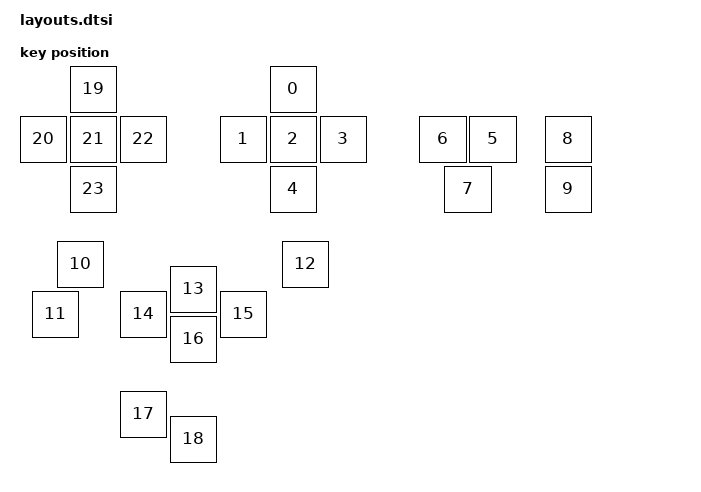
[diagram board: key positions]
#include <physical_layouts.dtsi>

/ {
    physical_layout0: physical_layout0 {
        compatible = "zmk,physical-layout";
        display-name = "Layout";
        keys
          =<&key_physical_attrs 100 100 500 0 0 0 0>
,<&key_physical_attrs 100 100 400 100 0 0 0>
,<&key_physical_attrs 100 100 500 100 0 0 0>
,<&key_physical_attrs 100 100 600 100 0 0 0>
,<&key_physical_attrs 100 100 500 200 0 0 0>
,<&key_physical_attrs 100 100 900 100 0 0 0>
,<&key_physical_attrs 100 100 800 100 0 0 0>
,<&key_physical_attrs 100 100 850 200 0 0 0>
,<&key_physical_attrs 100 100 1050 100 0 0 0>
,<&key_physical_attrs 100 100 1050 200 0 0 0>
,<&key_physical_attrs 100 100 75 350 0 0 0>
,<&key_physical_attrs 100 100 25 450 0 0 0>
,<&key_physical_attrs 100 100 525 350 0 0 0>
,<&key_physical_attrs 100 100 300 400 0 0 0>
,<&key_physical_attrs 100 100 200 450 0 0 0>
,<&key_physical_attrs 100 100 400 450 0 0 0>
,<&key_physical_attrs 100 100 300 500 0 0 0>
,<&key_physical_attrs 100 100 200 650 0 0 0>
,<&key_physical_attrs 100 100 300 700 0 0 0>
,<&key_physical_attrs 100 100 100 0 0 0 0>
,<&key_physical_attrs 100 100 0 100 0 0 0>
,<&key_physical_attrs 100 100 100 100 0 0 0>
,<&key_physical_attrs 100 100 200 100 0 0 0>
,<&key_physical_attrs 100 100 100 200 0 0 0>
            ;
    };
 };
